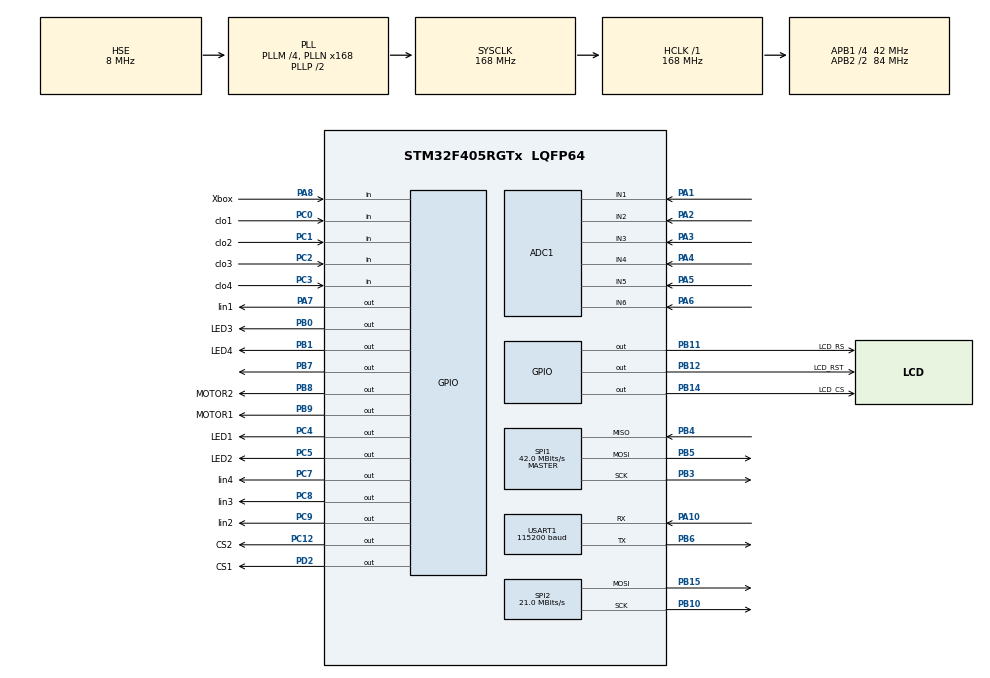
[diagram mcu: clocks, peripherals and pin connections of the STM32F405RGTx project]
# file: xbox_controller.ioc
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ADC1.Channel-0\#ChannelRegularConversion=ADC_CHANNEL_1
ADC1.Channel-1\#ChannelRegularConversion=ADC_CHANNEL_2
ADC1.Channel-2\#ChannelRegularConversion=ADC_CHANNEL_3
ADC1.Channel-3\#ChannelRegularConversion=ADC_CHANNEL_4
ADC1.Channel-4\#ChannelRegularConversion=ADC_CHANNEL_5
ADC1.Channel-5\#ChannelRegularConversion=ADC_CHANNEL_6
ADC1.ContinuousConvMode=ENABLE
ADC1.DMAContinuousRequests=ENABLE
ADC1.DiscontinuousConvMode=DISABLE
ADC1.NbrOfConversion=6
ADC1.NbrOfConversionFlag=1
ADC1.Rank-0\#ChannelRegularConversion=1
ADC1.Rank-1\#ChannelRegularConversion=2
ADC1.Rank-2\#ChannelRegularConversion=3
ADC1.Rank-3\#ChannelRegularConversion=4
ADC1.Rank-4\#ChannelRegularConversion=5
ADC1.Rank-5\#ChannelRegularConversion=6
ADC1.SamplingTime-0\#ChannelRegularConversion=ADC_SAMPLETIME_480CYCLES
ADC1.SamplingTime-1\#ChannelRegularConversion=ADC_SAMPLETIME_480CYCLES
ADC1.SamplingTime-2\#ChannelRegularConversion=ADC_SAMPLETIME_480CYCLES
ADC1.SamplingTime-3\#ChannelRegularConversion=ADC_SAMPLETIME_480CYCLES
ADC1.SamplingTime-4\#ChannelRegularConversion=ADC_SAMPLETIME_480CYCLES
ADC1.SamplingTime-5\#ChannelRegularConversion=ADC_SAMPLETIME_480CYCLES
ADC1.ScanConvMode=ENABLE
ADC1.master=1
Dma.ADC1.0.Direction=DMA_PERIPH_TO_MEMORY
Dma.ADC1.0.FIFOMode=DMA_FIFOMODE_DISABLE
Dma.ADC1.0.Instance=DMA2_Stream0
Dma.ADC1.0.MemDataAlignment=DMA_MDATAALIGN_HALFWORD
Dma.ADC1.0.MemInc=DMA_MINC_ENABLE
Dma.ADC1.0.Mode=DMA_CIRCULAR
Dma.ADC1.0.PeriphDataAlignment=DMA_PDATAALIGN_HALFWORD
Dma.ADC1.0.PeriphInc=DMA_PINC_DISABLE
Dma.ADC1.0.Priority=DMA_PRIORITY_LOW
Dma.Request0=ADC1
Dma.Request1=SPI1_RX
Dma.Request2=SPI1_TX
Dma.Request3=USART1_RX
Dma.Request4=USART1_TX
Dma.SPI1_RX.1.Direction=DMA_PERIPH_TO_MEMORY
Dma.SPI1_RX.1.FIFOMode=DMA_FIFOMODE_DISABLE
Dma.SPI1_RX.1.Instance=DMA2_Stream2
Dma.SPI1_RX.1.MemDataAlignment=DMA_MDATAALIGN_BYTE
Dma.SPI1_RX.1.MemInc=DMA_MINC_ENABLE
Dma.SPI1_RX.1.Mode=DMA_NORMAL
Dma.SPI1_RX.1.PeriphDataAlignment=DMA_PDATAALIGN_BYTE
Dma.SPI1_RX.1.PeriphInc=DMA_PINC_DISABLE
Dma.SPI1_RX.1.Priority=DMA_PRIORITY_VERY_HIGH
Dma.SPI1_TX.2.Direction=DMA_MEMORY_TO_PERIPH
Dma.SPI1_TX.2.FIFOMode=DMA_FIFOMODE_DISABLE
Dma.SPI1_TX.2.Instance=DMA2_Stream3
Dma.SPI1_TX.2.MemDataAlignment=DMA_MDATAALIGN_BYTE
Dma.SPI1_TX.2.MemInc=DMA_MINC_ENABLE
Dma.SPI1_TX.2.Mode=DMA_NORMAL
Dma.SPI1_TX.2.PeriphDataAlignment=DMA_PDATAALIGN_BYTE
Dma.SPI1_TX.2.PeriphInc=DMA_PINC_DISABLE
Dma.SPI1_TX.2.Priority=DMA_PRIORITY_HIGH
Dma.USART1_RX.3.Direction=DMA_PERIPH_TO_MEMORY
Dma.USART1_RX.3.FIFOMode=DMA_FIFOMODE_DISABLE
Dma.USART1_RX.3.Instance=DMA2_Stream5
Dma.USART1_RX.3.MemDataAlignment=DMA_MDATAALIGN_BYTE
Dma.USART1_RX.3.MemInc=DMA_MINC_ENABLE
Dma.USART1_RX.3.Mode=DMA_NORMAL
Dma.USART1_RX.3.PeriphDataAlignment=DMA_PDATAALIGN_BYTE
Dma.USART1_RX.3.PeriphInc=DMA_PINC_DISABLE
Dma.USART1_RX.3.Priority=DMA_PRIORITY_MEDIUM
Dma.USART1_TX.4.Direction=DMA_MEMORY_TO_PERIPH
Dma.USART1_TX.4.FIFOMode=DMA_FIFOMODE_DISABLE
Dma.USART1_TX.4.Instance=DMA2_Stream7
Dma.USART1_TX.4.MemDataAlignment=DMA_MDATAALIGN_BYTE
Dma.USART1_TX.4.MemInc=DMA_MINC_ENABLE
Dma.USART1_TX.4.Mode=DMA_NORMAL
Dma.USART1_TX.4.PeriphDataAlignment=DMA_PDATAALIGN_BYTE
Dma.USART1_TX.4.PeriphInc=DMA_PINC_DISABLE
Dma.USART1_TX.4.Priority=DMA_PRIORITY_MEDIUM
FREERTOS.Tasks01=defaultTask,0,128,StartDefaultTask,Default,NULL,Dynamic,NULL,NULL
Mcu.Family=STM32F4
Mcu.Name=STM32F405RGTx
Mcu.Package=LQFP64
NVIC.DMA2_Stream0_IRQn=true\:5\:0\:false\:false\:true\:true\:false\:true\:true
NVIC.DMA2_Stream2_IRQn=true\:5\:0\:false\:false\:true\:true\:false\:true\:true
NVIC.DMA2_Stream3_IRQn=true\:5\:0\:false\:false\:true\:true\:false\:true\:true
NVIC.DMA2_Stream5_IRQn=true\:5\:0\:false\:false\:true\:true\:false\:true\:true
NVIC.DMA2_Stream7_IRQn=true\:5\:0\:false\:false\:true\:true\:false\:true\:true
NVIC.PriorityGroup=NVIC_PRIORITYGROUP_4
NVIC.TIM8_TRG_COM_TIM14_IRQn=true\:15\:0\:false\:false\:true\:false\:false\:true\:true
NVIC.TimeBase=TIM8_TRG_COM_TIM14_IRQn
NVIC.TimeBaseIP=TIM14
NVIC.USART1_IRQn=true\:5\:0\:false\:false\:true\:true\:true\:true\:true
PA1.Signal=ADCx_IN1
PA10.Mode=Asynchronous
PA10.Signal=USART1_RX
PA13.Mode=Serial_Wire
PA13.Signal=SYS_JTMS-SWDIO
PA14.Mode=Serial_Wire
PA14.Signal=SYS_JTCK-SWCLK
PA2.Signal=ADCx_IN2
PA3.Signal=ADCx_IN3
PA4.Signal=ADCx_IN4
PA5.Signal=ADCx_IN5
PA6.Signal=ADCx_IN6
PA7.GPIO_Label=lin1
PA7.GPIO_PuPd=GPIO_NOPULL
PA7.GPIO_Speed=GPIO_SPEED_FREQ_HIGH
PA7.PinState=GPIO_PIN_SET
PA7.Signal=GPIO_Output
PA8.GPIO_Label=Xbox
PA8.GPIO_PuPd=GPIO_PULLUP
PA8.Signal=GPIO_Input
PB0.GPIO_Label=LED3
PB0.GPIO_PuPd=GPIO_PULLDOWN
PB0.Signal=GPIO_Output
PB1.GPIO_Label=LED4
PB1.GPIO_PuPd=GPIO_PULLDOWN
PB1.Signal=GPIO_Output
PB10.Mode=TX_Only_Simplex_Unidirect_Master
PB10.Signal=SPI2_SCK
PB11.GPIO_Label=LCD_RS
PB11.GPIO_Speed=GPIO_SPEED_FREQ_VERY_HIGH
PB11.Signal=GPIO_Output
PB12.GPIO_Label=LCD_RST
PB12.GPIO_Speed=GPIO_SPEED_FREQ_VERY_HIGH
PB12.Signal=GPIO_Output
PB14.GPIO_Label=LCD_CS
PB14.GPIO_Speed=GPIO_SPEED_FREQ_VERY_HIGH
PB14.Signal=GPIO_Output
PB15.Mode=TX_Only_Simplex_Unidirect_Master
PB15.Signal=SPI2_MOSI
PB3.Mode=Full_Duplex_Master
PB3.Signal=SPI1_SCK
PB4.Mode=Full_Duplex_Master
PB4.Signal=SPI1_MISO
PB5.Mode=Full_Duplex_Master
PB5.Signal=SPI1_MOSI
PB6.Mode=Asynchronous
PB6.Signal=USART1_TX
PB7.GPIO_PuPd=GPIO_PULLUP
PB7.GPIO_Speed=GPIO_SPEED_FREQ_MEDIUM
PB7.PinState=GPIO_PIN_RESET
PB7.Signal=GPIO_Output
PB8.GPIO_Label=MOTOR2
PB8.GPIO_PuPd=GPIO_PULLDOWN
PB8.GPIO_Speed=GPIO_SPEED_FREQ_MEDIUM
PB8.Signal=GPIO_Output
PB9.GPIO_Label=MOTOR1
PB9.GPIO_PuPd=GPIO_PULLDOWN
PB9.GPIO_Speed=GPIO_SPEED_FREQ_MEDIUM
PB9.Signal=GPIO_Output
PC0.GPIO_Label=clo1
PC0.GPIO_Mode=GPIO_MODE_INPUT
PC0.GPIO_PuPd=GPIO_PULLUP
PC0.Signal=GPIO_Input
PC1.GPIO_Label=clo2
PC1.GPIO_Mode=GPIO_MODE_INPUT
PC1.GPIO_PuPd=GPIO_PULLUP
PC1.Signal=GPIO_Input
PC12.GPIO_Label=CS2
PC12.GPIO_ModeDefaultOutputPP=GPIO_MODE_OUTPUT_PP
PC12.GPIO_PuPd=GPIO_PULLUP
PC12.GPIO_Speed=GPIO_SPEED_FREQ_HIGH
PC12.PinState=GPIO_PIN_SET
PC12.Signal=GPIO_Output
PC2.GPIO_Label=clo3
PC2.GPIO_PuPd=GPIO_PULLUP
PC2.Signal=GPIO_Input
PC3.GPIO_Label=clo4
PC3.GPIO_PuPd=GPIO_PULLUP
PC3.Signal=GPIO_Input
PC4.GPIO_Label=LED1
PC4.GPIO_PuPd=GPIO_PULLDOWN
PC4.Signal=GPIO_Output
PC5.GPIO_Label=LED2
PC5.GPIO_PuPd=GPIO_PULLDOWN
PC5.Signal=GPIO_Output
PC7.GPIO_Label=lin4
PC7.GPIO_PuPd=GPIO_PULLUP
PC7.GPIO_Speed=GPIO_SPEED_FREQ_HIGH
PC7.PinState=GPIO_PIN_SET
PC7.Signal=GPIO_Output
PC8.GPIO_Label=lin3
PC8.GPIO_PuPd=GPIO_PULLUP
PC8.GPIO_Speed=GPIO_SPEED_FREQ_HIGH
PC8.PinState=GPIO_PIN_SET
PC8.Signal=GPIO_Output
PC9.GPIO_Label=lin2
PC9.GPIO_ModeDefaultOutputPP=GPIO_MODE_OUTPUT_PP
PC9.GPIO_PuPd=GPIO_PULLUP
PC9.GPIO_Speed=GPIO_SPEED_FREQ_HIGH
PC9.PinState=GPIO_PIN_SET
PC9.Signal=GPIO_Output
PD2.GPIO_Label=CS1
PD2.GPIO_ModeDefaultOutputPP=GPIO_MODE_OUTPUT_PP
PD2.GPIO_PuPd=GPIO_PULLUP
PD2.GPIO_Speed=GPIO_SPEED_FREQ_HIGH
PD2.PinState=GPIO_PIN_SET
PD2.Signal=GPIO_Output
PH0-OSC_IN.Mode=HSE-External-Oscillator
PH0-OSC_IN.Signal=RCC_OSC_IN
PH1-OSC_OUT.Mode=HSE-External-Oscillator
PH1-OSC_OUT.Signal=RCC_OSC_OUT
ProjectManager.HeapSize=0x200
ProjectManager.StackSize=0x400
ProjectManager.TargetToolchain=CMake
RCC.48MHZClocksFreq_Value=84000000
RCC.AHBFreq_Value=168000000
RCC.APB1CLKDivider=RCC_HCLK_DIV4
RCC.APB1Freq_Value=42000000
RCC.APB1TimFreq_Value=84000000
RCC.APB2CLKDivider=RCC_HCLK_DIV2
RCC.APB2Freq_Value=84000000
RCC.APB2TimFreq_Value=168000000
RCC.CortexFreq_Value=168000000
RCC.HCLKFreq_Value=168000000
RCC.HSE_VALUE=8000000
RCC.HSI_VALUE=16000000
RCC.LSE_VALUE=32768
RCC.PLLM=4
RCC.PLLN=168
RCC.PLLSourceVirtual=RCC_PLLSOURCE_HSE
RCC.SYSCLKFreq_VALUE=168000000
RCC.SYSCLKSource=RCC_SYSCLKSOURCE_PLLCLK
RCC.VCOOutputFreq_Value=336000000
SH.ADCx_IN1.0=ADC1_IN1,IN1
SH.ADCx_IN2.0=ADC1_IN2,IN2
SH.ADCx_IN3.0=ADC1_IN3,IN3
SH.ADCx_IN4.0=ADC1_IN4,IN4
SH.ADCx_IN5.0=ADC1_IN5,IN5
SH.ADCx_IN6.0=ADC1_IN6,IN6
SPI1.CalculateBaudRate=42.0 MBits/s
SPI1.Direction=SPI_DIRECTION_2LINES
SPI1.Mode=SPI_MODE_MASTER
SPI1.VirtualType=VM_MASTER
SPI2.CalculateBaudRate=21.0 MBits/s
SPI2.Direction=SPI_DIRECTION_2LINES
SPI2.Mode=SPI_MODE_MASTER
SPI2.VirtualType=VM_MASTER
STMicroelectronics.X-CUBE-ALGOBUILD.1.4.0.LibraryCcDSPOoLibraryJjDSPOoLibrary=true
TIM2.AutoReloadPreload=TIM_AUTORELOAD_PRELOAD_ENABLE
TIM2.Period=9999
TIM2.Prescaler=16799
USART1.BaudRate=115200
USART1.VirtualMode=VM_ASYNC
VP_FREERTOS_VS_CMSIS_V1.Mode=CMSIS_V1
VP_STMicroelectronics.X-CUBE-ALGOBUILD_VS_DSPOoLibraryJjLibrary_1.4.0_1.4.0.Mode=DSPOoLibraryJjLibrary
VP_SYS_VS_tim14.Mode=TIM14
VP_TIM2_VS_ClockSourceINT.Mode=Internal
board=custom

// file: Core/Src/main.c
/* USER CODE BEGIN Header */
/**
 ******************************************************************************
 * @file           : main.c
 * @brief          : Main program body
 ******************************************************************************
 * @attention
 *
 * Copyright (c) 2025 STMicroelectronics.
 * All rights reserved.
 *
 * This software is licensed under terms that can be found in the LICENSE file
 * in the root directory of this software component.
 * If no LICENSE file comes with this software, it is provided AS-IS.
 *
 ******************************************************************************
 */
/* USER CODE END Header */
#include "main.h"

#include "adc.h"
#include "cmsis_os.h"
#include "dma.h"
#include "gpio.h"
#include "spi.h"
#include "tim.h"
#include "usart.h"

/* USER CODE BEGIN Includes */
#include "GUI.h"
#include "xbox.h"
/* USER CODE END Includes */

void SystemClock_Config(void);
void MX_FREERTOS_Init(void);

int main(void) {

  /* MCU Configuration--------------------------------------------------------*/

  /* Reset of all peripherals, Initializes the Flash interface and the Systick.
   */
  HAL_Init();

  /* Configure the system clock */
  SystemClock_Config();

  /* Initialize all configured peripherals */
  MX_GPIO_Init();
  MX_DMA_Init();
  MX_SPI2_Init();
  MX_ADC1_Init();
  MX_USART1_UART_Init();
  MX_SPI1_Init();
  MX_TIM2_Init();
  /* USER CODE BEGIN 2 */
  LCD_Init();

  // GUI_DrawFont16(1, 5, BLACK, WHITE, "5", 1);
  // gui_circle(160, 64, RED, 60, 0);
  // float a=5.5;
  // Show_Str(16, 20, RED, WHITE, "Finish locking", 20, 1);
  // Show_Str(16,50, BLACK, WHITE, "Yolo error:", 20, 1);
  // LCD_ShowNum(110,50, (int)a, 1, 20);

  // LCD_ShowNum(16,8,123456,6,16);
  // Show_Str(16,40,BLACK,WHITE,"ABCDEFG",16,0);//��ʾ16����???????
  // Show_Str(16,72,BLACK,WHITE,"��ʾ",16,0);//��ʾ16����???????
  // Show_Str(16,104,BLACK,WHITE,"����",24,0);//��ʾ24����???????
  // Show_Str(16,136,BLACK,WHITE,"����",32,0);//��ʾ32����???????
  // ������ɫ����
  // LCD_Fill(0,130,128,140,BLUE);
  // LCD_Fill(0,140,128,150,GREEN);
  // LCD_Fill(0,150,128,160,RED);
  // HAL_GPIO_WritePin(GPIOB, GPIO_PIN_7, GPIO_PIN_RESET);
  XboxInit();

  /* USER CODE END 2 */

  /* Call init function for freertos objects (in cmsis_os2.c) */
  MX_FREERTOS_Init();

  // /* Start scheduler */
  osKernelStart();

  /* We should never get here as control is now taken by the scheduler */

  /* Infinite loop */
  while (1) {

  }
}

void SystemClock_Config(void) {
  RCC_OscInitTypeDef RCC_OscInitStruct = {0};
  RCC_ClkInitTypeDef RCC_ClkInitStruct = {0};

  /** Configure the main internal regulator output voltage
   */
  __HAL_RCC_PWR_CLK_ENABLE();
  __HAL_PWR_VOLTAGESCALING_CONFIG(PWR_REGULATOR_VOLTAGE_SCALE1);

  /** Initializes the RCC Oscillators according to the specified parameters
   * in the RCC_OscInitTypeDef structure.
   */
  RCC_OscInitStruct.OscillatorType = RCC_OSCILLATORTYPE_HSE;
  RCC_OscInitStruct.HSEState = RCC_HSE_ON;
  RCC_OscInitStruct.PLL.PLLState = RCC_PLL_ON;
  RCC_OscInitStruct.PLL.PLLSource = RCC_PLLSOURCE_HSE;
  RCC_OscInitStruct.PLL.PLLM = 4;
  RCC_OscInitStruct.PLL.PLLN = 168;
  RCC_OscInitStruct.PLL.PLLP = RCC_PLLP_DIV2;
  RCC_OscInitStruct.PLL.PLLQ = 4;
  if (HAL_RCC_OscConfig(&RCC_OscInitStruct) != HAL_OK) {
    Error_Handler();
  }

  /** Initializes the CPU, AHB and APB buses clocks
   */
  RCC_ClkInitStruct.ClockType = RCC_CLOCKTYPE_HCLK | RCC_CLOCKTYPE_SYSCLK |
                                RCC_CLOCKTYPE_PCLK1 | RCC_CLOCKTYPE_PCLK2;
  RCC_ClkInitStruct.SYSCLKSource = RCC_SYSCLKSOURCE_PLLCLK;
  RCC_ClkInitStruct.AHBCLKDivider = RCC_SYSCLK_DIV1;
  RCC_ClkInitStruct.APB1CLKDivider = RCC_HCLK_DIV4;
  RCC_ClkInitStruct.APB2CLKDivider = RCC_HCLK_DIV2;

  if (HAL_RCC_ClockConfig(&RCC_ClkInitStruct, FLASH_LATENCY_5) != HAL_OK) {
    Error_Handler();
  }
}

void HAL_TIM_PeriodElapsedCallback(TIM_HandleTypeDef *htim) {
  if (htim->Instance == TIM14) {
    HAL_IncTick();
  }
}

void Error_Handler(void) {
  __disable_irq();
  while (1) {
  }
}

#ifdef USE_FULL_ASSERT
/**
 * @brief  Reports the name of the source file and the source line number
 *         where the assert_param error has occurred.
 * @param  file: pointer to the source file name
 * @param  line: assert_param error line source number
 * @retval None
 */
void assert_failed(uint8_t *file, uint32_t line) {
  /* USER CODE BEGIN 6 */
  /* User can add his own implementation to report the file name and line
     number, ex: printf("Wrong parameters value: file %s on line %d\r\n", file,
     line) */
  /* USER CODE END 6 */
}
#endif /* USE_FULL_ASSERT */
